# F28x7x_mcbsp_regs register map
Vendor: Texas Instruments
Peripheral module from a debugger description file (folder C2000).
Address unit: 16 bits
Registers are 16-bit, read-write, no defined reset value unless marked. A register's access mark holds for its fields unless they carry their own. Offsets are as the file gives them; lines under a group give offsets from that group; [hi:lo] are bit positions; {n}, {i} and the like mark numbered series; 'fields as' and 'values as' point back to an identical list; <NAME> marks a mode.

## MCBSP_REGS
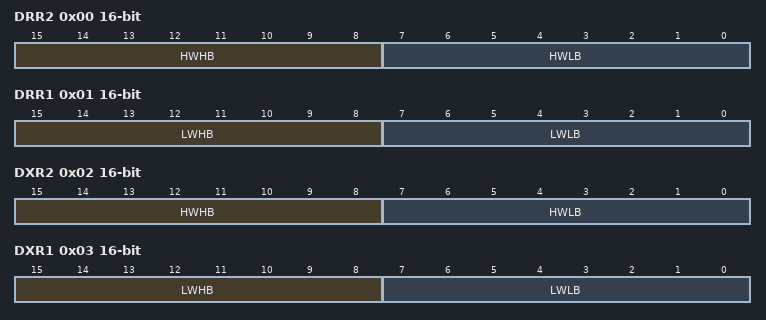
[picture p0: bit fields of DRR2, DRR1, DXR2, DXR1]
0x00 DRR2 — Data receive register bits 31-16
  [15:8] HWHB — High word high byte
  [7:0] HWLB — High word low byte
0x01 DRR1 — Data receive register bits 15-0
  [15:8] LWHB — Low word high byte
  [7:0] LWLB — Low word low byte
0x02 DXR2 — Data transmit register bits 31-16
  [15:8] HWHB — High word high byte
  [7:0] HWLB — High word low byte
0x03 DXR1 — Data transmit register bits 15-0
  [15:8] LWHB — Low word high byte
  [7:0] LWLB — Low word low byte
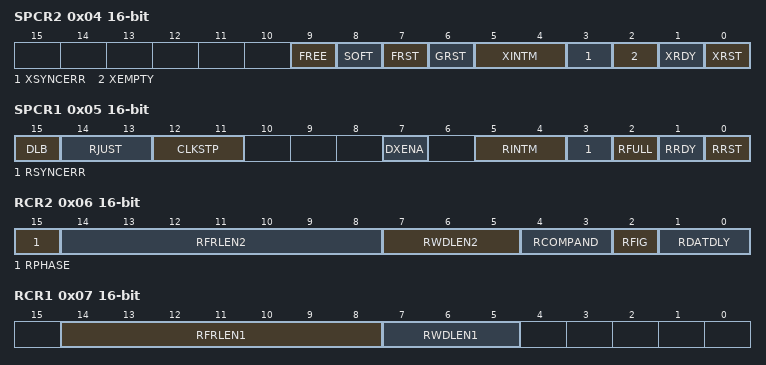
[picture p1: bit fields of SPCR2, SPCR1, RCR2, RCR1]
0x04 SPCR2 — Control register 2
  [9] FREE — FREE bit
  [8] SOFT — SOFT bit
  [7] FRST — Frame sync logic reset
    0=If you read a 0, the frame-synchronization logic is in its rese; 1=If you read a 1, the frame-synchronization logic is enabled
  [6] GRST — Sample rate generator reset
    0=If you read a 0, the sample rate generator is in its reset stat; 1=If you read a 1, the sample rate generator is enabled
  [5:4] XINTM — Transmit Interupt mode bits
    0=The McBSP sends a transmit interrupt (XINT) request to the CPU; 1=In the multichannel selection mode, the McBSP sends an XINT req; 2=__2 (The McBSP sends an XINT request to the CPU when each transmit f); 3=__3 (The McBSP sends an XINT request to the CPU when the XSYNCERR bi)
  [3] XSYNCERR — Transmit sync error INT flag
    0=No error; 1=Transmit frame-synchronization error
  [2] XEMPTY — Transmitter empty
    0=Transmitter-empty condition[[br]]Typically this indicates that; 1=No transmitter-empty condition
  [1] XRDY — Transmitter ready
    0=Transmitter not ready[[br]]When DXR1 is loaded, XRDY is automat; 1=Transmitter ready: DXR[1,2] is ready to accept new data
  [0] XRST — Transmitter reset
    0=If you read a 0, the transmitter is in its reset state; 1=If you read a 1, the transmitter is enabled
0x05 SPCR1 — Control register 1
  [15] DLB — Digital loopback
    0=Disabled[[br]]Internal DR is supplied by the MDRx pin; 1=Enabled[[br]]Internal receive signals are supplied by internal
  [14:13] RJUST — Rx sign extension and justification mode
    0=Right justify the data and zero fill the MSBs; 1=Right justify the data and sign-extend the data into the MSBs; 2=__2 (Left justify the data and zero fill the LSBs); 3=__3 (Reserved (do not use))
  [12:11] CLKSTP — Clock stop mode
    0=Clock stop mode is disabled; 1=Clock stop mode is disabled; 2=__2 (Clock stop mode, without clock delay); 3=__3 (Clock stop mode, with half-cycle clock delay)
  [7] DXENA — DX delay enable
    0=DX delay enabler off; 1=DX delay enabler on
  [5:4] RINTM — Receive Interupt mode bits
    0=The McBSP sends a receive interrupt (RINT) request to the CPU w; 1=In the multichannel selection mode, the McBSP sends a RINT requ; 2=__2 (The McBSP sends a RINT request to the CPU when each receive fra); 3=__3 (The McBSP sends a RINT request to the CPU when the RSYNCERR bit)
  [3] RSYNCERR — Receive sync error INT flag
    0=No error; 1=Receive frame-synchronization error
  [2] RFULL — Receiver full
    0=No receiver-full condition; 1=Receiver-full condition: RSR[1,2] and RBR[1,2] are full with ne
  [1] RRDY — Receiver ready
    0=Receiver not ready[[br]]When the content of DRR1 is read, RRDY; 1=Receiver ready: New data can be read from DRR[1,2]
  [0] RRST — Receiver reset
    0=If you read a 0, the receiver is in its reset state; 1=If you read a 1, the receiver is enabled
0x06 RCR2 — Receive Control register 2
  [15] RPHASE — Receive Phase
    0=Single-phase frame[[br]]The receive frame has only one phase, p; 1=Dual-phase frame[[br]]The receive frame has two phases, phase 1
  [14:8] RFRLEN2 — Receive Frame length 2
  [7:5] RWDLEN2 — Receive word length 2
    0=8 bits; 1=12 bits; 2=__2 (16 bits); 3=__3 (20 bits); 4=__4 (24 bits); 5=__5 (32 bits); 6=__6 (Reserved (do not use)); 7=__7 (Reserved (do not use))
  [4:3] RCOMPAND — Receive Companding Mode selects
    0=No companding, any size data, MSB received first; 1=No companding, 8-bit data, LSB received first; 2=__2 (?-law companding, 8-bit data, MSB received first); 3=__3 (A-law companding, 8-bit data, MSB received first)
  [2] RFIG — Receive frame sync ignore
    0=Frame-synchronization detect; 1=Frame-synchronization ignore
  [1:0] RDATDLY — Receive data delay
    0=0-bit data delay; 1=1-bit data delay; 2=__2 (2-bit data delay); 3=__3 (Reserved (do not use))
0x07 RCR1 — Receive Control register 1
  [14:8] RFRLEN1 — Receive Frame length 1
  [7:5] RWDLEN1 — Receive word length 1
    values as RCR2.RWDLEN2
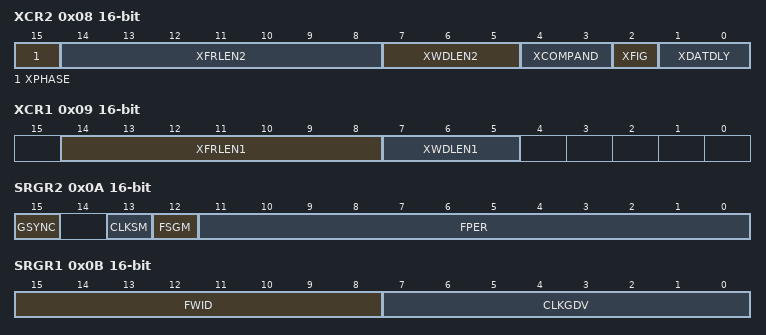
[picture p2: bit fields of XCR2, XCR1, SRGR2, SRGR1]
0x08 XCR2 — Transmit Control register 2
  [15] XPHASE — Transmit Phase
  [14:8] XFRLEN2 — Transmit Frame length 2
  [7:5] XWDLEN2 — Transmit word length 2
    values as RCR2.RWDLEN2
  [4:3] XCOMPAND — Transmit Companding Mode selects
    values as RCR2.RCOMPAND
  [2] XFIG — Transmit frame sync ignore
    values as RCR2.RFIG
  [1:0] XDATDLY — Transmit data delay
    values as RCR2.RDATDLY
0x09 XCR1 — Transmit Control register 1
  [14:8] XFRLEN1 — Transmit Frame length 1
  [7:5] XWDLEN1 — Transmit word length 1
    values as RCR2.RWDLEN2
0x0A SRGR2 — Sample rate generator register 2
  [15] GSYNC — CLKG sync
    0=No clock synchronization[[br]]CLKG oscillates without adjustmen; 1=Clock synchronization[[br]]- CLKG is adjusted as necessary so t
  [13] CLKSM — Sample rate generator mode
    0=Sample rate generator input clock mode bit; 1=The input clock for the sample rate generator is taken from the
  [12] FSGM — Frame sync generator mode
    0=If FSXM = 1, the McBSP generates a transmit frame-synchronizati; 1=If FSXM = 1, the transmitter uses frame-synchronization pulses
  [11:0] FPER — Frame-sync period
0x0B SRGR1 — Sample rate generator register 1
  [15:8] FWID — Frame width
  [7:0] CLKGDV — CLKG divider
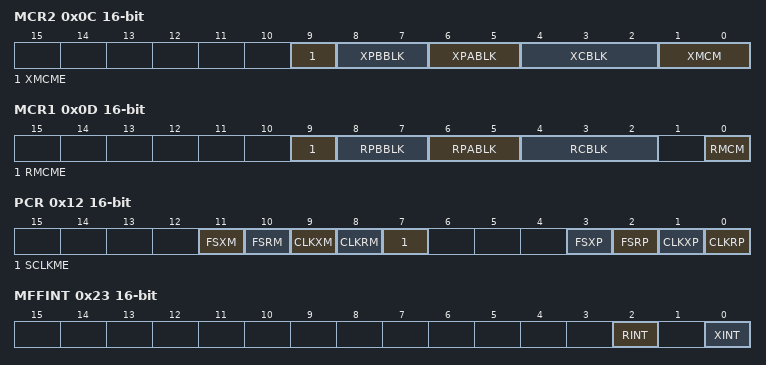
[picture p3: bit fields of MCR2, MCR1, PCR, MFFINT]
0x0C MCR2 — Multi-channel register 2
  [9] XMCME — Transmit Frame length 2
  [8:7] XPBBLK — Transmit word length 2
    0=Block 1: channels 16 through 31; 1=Block 3: channels 48 through 63; 2=__2 (Block 5: channels 80 through 95); 3=__3 (Block 7: channels 112 through 127)
  [6:5] XPABLK — Transmit Companding Mode selects
    0=Block 0: channels 0 through 15; 1=Block 2: channels 32 through 47; 2=__2 (Block 4: channels 64 through 79); 3=__3 (Block 6: channels 96 through 111)
  [4:2] XCBLK — Transmit frame sync ignore
    0=Block 0: channels 0 through 15; 1=Block 1: channels 16 through 31; 2=__2 (Block 2: channels 32 through 47); 3=__3 (Block 3: channels 48 through 63); 4=__4 (Block 4: channels 64 through 79); 5=__5 (Block 5: channels 80 through 95); 6=__6 (Block 6: channels 96 through 111); 7=__7 (Block 7: channels 112 through 127)
  [1:0] XMCM — Transmit data delay
    0=No transmit multichannel selection mode is on; 1=All channels are disabled unless they are selected in the appro; 2=__2 (All channels are enabled, but they are masked unless they are s); 3=__3 (This mode is used for symmetric transmission and reception)
0x0D MCR1 — Multi-channel register 1
  [9] RMCME — Receive multi-channel enhance mode
    0=2-partition mode[[br]]Only partitions A and B are used; 1=8-partition mode[[br]]All partitions (A through H) are used
  [8:7] RPBBLK — Receive partition B Block
    values as MCR2.XPBBLK
  [6:5] RPABLK — Receive partition A Block
    values as MCR2.XPABLK
  [4:2] RCBLK — eceive current block
    values as MCR2.XCBLK
  [0] RMCM — Receive multichannel mode
    0=All 128 channels are enabled; 1=Multichanneled selection mode
0x0E RCERA — Receive channel enable partition A
  [15:0] RCEA — Receive channel enable bit.
    0=Disable the channel that is mapped to RCEx; 1=Enable the channel that is mapped to RCEx
0x0F RCERB — Receive channel enable partition B
  [15:0] RCEB — Receive channel enable bit.
    values as RCERA.RCEA
0x10 XCERA — Transmit channel enable partition A
  [15:0] XCERA — Transmit Channel enable bit
    0=For multichannel selection when XMCM =; 1=For multichannel selection when XMCM =
0x11 XCERB — Transmit channel enable partition B
  [15:0] XCERB — Transmit Channel enable bit
    values as XCERA.XCERA
0x12 PCR — Pin Control register
  [11] FSXM — Transmit Frame Synchronization Mode
    0=Transmit frame synchronization is supplied by an external sourc; 1=Transmit frame synchronization is generated internally by the S
  [10] FSRM — Receive Frame Synchronization Mode
    0=Receive frame synchronization is supplied by an external source; 1=Receive frame synchronization is supplied by the sample rate ge
  [9] CLKXM — Transmit Clock Mode.
    0=Not in clock stop mode (CLKSTP =; 1=Not in clock stop mode (CLKSTP =
  [8] CLKRM — Receiver Clock Mode
    0=Not in digital loopback mode (DLB = 0):[[br]]The MCLKR pin is a; 1=Not in digital loopback mode (DLB = 0):[[br]]Internal MCLKR is
  [7] SCLKME — Sample clock mode selection
  [3] FSXP — Transmit Frame synchronization polarity
    0=Transmit frame-synchronization pulses are active high; 1=Transmit frame-synchronization pulses are active low
  [2] FSRP — Receive Frame synchronization polarity
    0=Receive frame-synchronization pulses are active high; 1=Receive frame-synchronization pulses are active low
  [1] CLKXP — Transmit clock polarity
    0=Transmit data is sampled on the rising edge of CLKX; 1=Transmit data is sampled on the falling edge of CLKX
  [0] CLKRP — Receive Clock polarity
    0=Receive data is sampled on the falling edge of MCLKR; 1=Receive data is sampled on the rising edge of MCLKR
0x13 RCERC — Receive channel enable partition C
  [15:0] RCEC — Receive channel enable bit.
    values as RCERA.RCEA
0x14 RCERD — Receive channel enable partition D
  [15:0] RCED — Receive channel enable bit.
    values as RCERA.RCEA
0x15 XCERC — Transmit channel enable partition C
  [15:0] XCERC — Transmit Channel enable bit
    values as XCERA.XCERA
0x16 XCERD — Transmit channel enable partition D
  [15:0] XCERD — Transmit Channel enable bit
    values as XCERA.XCERA
0x17 RCERE — Receive channel enable partition E
  [15:0] RCEE — Receive channel enable bit.
    values as RCERA.RCEA
0x18 RCERF — Receive channel enable partition F
  [15:0] RCEF — Receive channel enable bit.
    values as RCERA.RCEA
0x19 XCERE — Transmit channel enable partition E
  [15:0] XCERE — Transmit Channel enable bit
    values as XCERA.XCERA
0x1A XCERF — Transmit channel enable partition F
  [15:0] XCERF — Transmit Channel enable bit
    values as XCERA.XCERA
0x1B RCERG — Receive channel enable partition G
  [15:0] RCEG — Receive channel enable bit.
    values as RCERA.RCEA
0x1C RCERH — Receive channel enable partition H
  [15:0] RCEH — Receive channel enable bit.
    values as RCERA.RCEA
0x1D XCERG — Transmit channel enable partition G
  [15:0] XCERG — Transmit Channel enable bit
    values as XCERA.XCERA
0x1E XCERH — Transmit channel enable partition H
  [15:0] XCERH — Transmit Channel enable bit
    values as XCERA.XCERA
0x23 MFFINT — Interrupt enable
  [2] RINT — Enable for transmit Interrupt
    0=Transmit interrupt on XRDY is disabled; 1=Transmit interrupt on XRDY is enabled
  [0] XINT — Enable for Receive Interrupt
    0=Receive interrupt on RRDY is disabled; 1=Receive interrupt on RRDY is enabled
